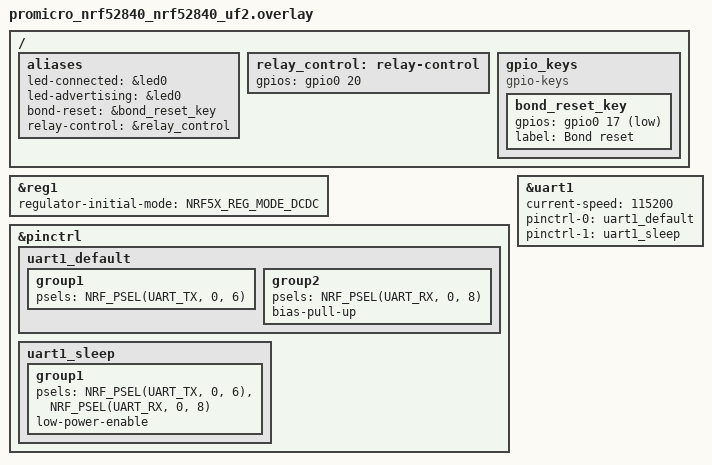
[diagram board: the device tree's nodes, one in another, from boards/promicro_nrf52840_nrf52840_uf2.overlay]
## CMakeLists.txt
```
cmake_minimum_required(VERSION 3.20.0)
find_package(Zephyr REQUIRED HINTS $ENV{ZEPHYR_BASE})

project(nrfProxy)

target_sources(app PRIVATE
	src/main.c
	src/proxy_core.c
	src/uart_bridge.c
	src/uart_rx_retry.c
	src/drop_stats.c
)
```

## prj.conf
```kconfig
# ---------------------------------------------------------------------------
# nrfProxy: forward incoming UART1 serial data to a phone over BLE (NUS)
# ---------------------------------------------------------------------------

# --- Bluetooth: BLE peripheral exposing the Nordic UART Service -------------
CONFIG_BT=y
CONFIG_BT_PERIPHERAL=y
CONFIG_BT_DEVICE_NAME="nrfProxy"
CONFIG_BT_MAX_CONN=1

# Per-device identity (see identity_init() in main.c): derive a stable
# random-static BT address and a unique "nrfProxy-XXXX" name suffix from the
# SoC's hardware ID, so multiple units are distinguishable over the air.
# HWINFO exposes that hardware ID; DEVICE_NAME_DYNAMIC lets bt_set_name() set
# the runtime name (MAX must fit "nrfProxy-XXXX").
CONFIG_HWINFO=y
CONFIG_BT_DEVICE_NAME_DYNAMIC=y
CONFIG_BT_DEVICE_NAME_MAX=20

# Nordic UART Service (NUS) — the GATT service the phone subscribes to
CONFIG_BT_NUS=y

# --- Pairing / bond-lock (see PAIRING_PLAN.md) -----------------------------
# Once a phone pairs, only that phone can reconnect: the bond is stored in
# flash, the filter accept list rejects everyone else at the link layer, and
# the link must reach security level 2 (encryption) before NUS data flows.
# A hardware button held during boot wipes the bond (back to pairing mode).
#
# Just Works pairing (no display/keypad -> unauthenticated but encrypted).
# CONFIG_BT_NUS_AUTHEN is deliberately NOT set: it demands MITM-authenticated
# pairing, which Just Works can never satisfy — encryption is enforced in the
# application layer instead (security_changed + a watchdog in main.c).
# MAX_PAIRED=1 makes the stack reject any second bond. These stay in prj.conf
# (not prod.conf): production needs the lock most of all.
CONFIG_BT_SMP=y
CONFIG_BT_BONDABLE=y
CONFIG_BT_MAX_PAIRED=1
CONFIG_BT_FILTER_ACCEPT_LIST=y

# Bond persistence: the settings subsystem stores the LTK/IRK in NVS in the DT
# storage_partition (all four boards define one — no overlay change needed).
# The bond survives power loss until the reset button wipes it.
CONFIG_BT_SETTINGS=y
CONFIG_SETTINGS=y
CONFIG_FLASH=y
CONFIG_FLASH_MAP=y
CONFIG_NVS=y

# Throughput: negotiate a larger ATT MTU and LL data length so we can push
# up to ~244 bytes per notification instead of the 20-byte default.
CONFIG_BT_L2CAP_TX_MTU=247
CONFIG_BT_BUF_ACL_TX_SIZE=251
CONFIG_BT_BUF_ACL_RX_SIZE=251
CONFIG_BT_CTLR_DATA_LENGTH_MAX=251

# --- Serial: async UART driver for the incoming data on UART1 --------------
CONFIG_SERIAL=y
CONFIG_UART_ASYNC_API=y
# uart1 is our async data port. The per-instance UART_1_ASYNC depends on
# !UART_1_INTERRUPT_DRIVEN, and UART_1_INTERRUPT_DRIVEN defaults y whenever
# anything enables CONFIG_UART_INTERRUPT_DRIVEN (e.g. the XIAO BLE's USB CDC
# console). Without this, uart_callback_set() returns -ENOSYS (-88) on those
# boards. Force it off so uart1 keeps the async API everywhere.
CONFIG_UART_1_INTERRUPT_DRIVEN=n
# Runtime baud change: the phone switches uart1's baud on the fly (different
# motor controllers talk at 1200..115200) via uart_configure() in uart_bridge.c.
# Without this, uart_configure()/uart_config_get() return -ENOSYS.
CONFIG_UART_USE_RUNTIME_CONFIGURE=y

# --- Misc ------------------------------------------------------------------
CONFIG_HEAP_MEM_POOL_SIZE=2048

# GPIO for the status LEDs
CONFIG_GPIO=y

# Logging on the default console (board-dependent: J-Link VCOM on the DK,
# USB CDC-ACM on the XIAO BLE)
CONFIG_LOG=y

# Board-specific debug/optimization settings live in the per-board fragments under
# boards/ that Zephyr auto-merges on top of this file — see README.md
# ("Per-board Kconfig fragments") for the full list.
```

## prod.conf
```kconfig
# No logging subsystem / output.
CONFIG_LOG=n

# Drop the USB CDC-ACM serial backend. On the XIAO this Kconfig (default y)
# pulls in the USB device stack and initialises CDC-ACM as the console at boot;
# turning it off removes USB bring-up entirely. The console then has no backend.
CONFIG_BOARD_SERIAL_BACKEND_CDC_ACM=n
CONFIG_CONSOLE=n
CONFIG_UART_CONSOLE=n
```

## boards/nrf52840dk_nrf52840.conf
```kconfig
# Board-specific Kconfig for the nRF52840 DK (bench/debug board).
# Auto-merged on top of prj.conf by Zephyr for `-b nrf52840dk/nrf52840`.
#
# Build at -Og and expose thread info so the SWD/J-Link debugger in VS Code
# can place breakpoints and enumerate threads. The XIAO (production) omits
# these for a smaller/faster -Os build.
CONFIG_DEBUG_OPTIMIZATIONS=y
CONFIG_DEBUG_THREAD_INFO=y
```

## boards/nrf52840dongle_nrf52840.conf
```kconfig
# Board-specific Kconfig for the Nordic nRF52840 Dongle (PCA10059).
# Auto-merged on top of prj.conf by Zephyr for `-b nrf52840dongle/nrf52840`.
#
# Debug/bench board: keep logging + the USB CDC-ACM console (the dongle has no
# debugger / VCOM). prj.conf already enables logging, so "debug output" works out
# of the box; these are the debug-build niceties on top.

# Debug aids (same as the DK's .conf): -Og and thread metadata for a debugger.
CONFIG_DEBUG_OPTIMIZATIONS=y
CONFIG_DEBUG_THREAD_INFO=y

# USB device controller buffer pool. The 1024-byte default is too small for the
# large control transfers a Windows host issues during enumeration, so EP0
# allocations fail ("udc: Failed to allocate net_buf 4095, ep 0x80") and log
# output over USB CDC-ACM is disrupted. Size the pool past the request.
# (Same issue as the XIAO / Pro Micro — Zephyr issue #85108.)
CONFIG_UDC_BUF_POOL_SIZE=8192

# Note: CONFIG_UART_1_INTERRUPT_DRIVEN=n lives in prj.conf (global) so uart1's
# async API isn't gated by the USB CDC-ACM console's CONFIG_UART_INTERRUPT_DRIVEN
# (the -ENOSYS trap documented in CLAUDE.md). It applies here too.
```

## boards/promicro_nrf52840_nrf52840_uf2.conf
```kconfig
# Board-specific Kconfig for the "Pro Micro nRF52840" / nice!nano clone.
# Auto-merged on top of prj.conf by Zephyr for `-b promicro_nrf52840/nrf52840[/uf2]`.
#
# Debug/bring-up build: keep the USB CDC-ACM console + logging (this board has no
# debug UART). For battery/production, layer prod.conf on top via EXTRA_CONF_FILE
# into a separate build dir, exactly like the XIAO (see prod.conf / CLAUDE.md).

# USB device controller buffer pool. The 1024-byte default is too small for the
# large control transfers a Windows host issues during enumeration, so EP0
# allocations fail ("udc: Failed to allocate net_buf 4095, ep 0x80") and log
# output over USB CDC-ACM is disrupted. Size the pool past the request.
# (Same issue as the XIAO — Zephyr issue #85108.)
CONFIG_UDC_BUF_POOL_SIZE=8192

# Note: CONFIG_UART_1_INTERRUPT_DRIVEN=n lives in prj.conf (global) so uart1's
# async API isn't gated by the USB CDC-ACM console's CONFIG_UART_INTERRUPT_DRIVEN
# (the -ENOSYS trap documented in CLAUDE.md). It applies here too.

# Low-frequency clock source: no override here on purpose. The promicro_nrf52840
# board target already defaults to the external 32.768 kHz crystal
# (CONFIG_CLOCK_CONTROL_NRF_K32SRC_XTAL), which this board populates — better
# accuracy / lower power than the internal RC. If you flash a crystal-less clone
# (many cheap Pro Micro / "SuperMini" boards omit the 32 kHz crystal), add
# CONFIG_CLOCK_CONTROL_NRF_K32SRC_RC=y + CONFIG_CLOCK_CONTROL_NRF_K32SRC_500PPM=y,
# or LFCLK never starts and the BLE controller blocks at bt_enable().
```

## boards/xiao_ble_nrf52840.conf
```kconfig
# Board-specific Kconfig for the Seeed XIAO BLE (production board).
# Auto-merged on top of prj.conf by Zephyr for `-b xiao_ble/nrf52840`.
#
# Production build: optimize for size, no debug build options. Logging still
# works (over USB CDC-ACM); this only drops the -Og/thread-info debug aids.
CONFIG_SIZE_OPTIMIZATIONS=y

# USB device controller buffer pool. The 1024-byte default is too small for the
# large control transfers a Windows host issues during enumeration, so EP0
# allocations fail ("udc: Failed to allocate net_buf 4095, ep 0x80") and log
# output over USB CDC-ACM is disrupted. Size the pool past the request.
# (Zephyr issue #85108.)
CONFIG_UDC_BUF_POOL_SIZE=8192
```

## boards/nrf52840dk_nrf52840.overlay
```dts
/*
 * nrfProxy — UART1 for incoming serial data on the nRF52840 DK.
 *
 * Wiring (share a common GND with your serial source!):
 *   Device TX  ->  P1.01  (DK RX)   serial device -> phone
 *   Device RX  <-  P1.02  (DK TX)   phone -> serial device
 *
 * P1.01 / P1.02 are free on the DK (no LED/button/QSPI/NFC conflict) and are
 * broken out on the GPIO headers. Change current-speed below to match your
 * source's baud rate (defaults to 115200).
 */

#include <zephyr/dt-bindings/pinctrl/nrf-pinctrl.h>
#include <zephyr/dt-bindings/gpio/gpio.h>

/ {
	/* Status-LED roles -> three of the DK's LEDs (LED2/LED3/LED4). */
	aliases {
		led-connected = &led1;
		led-advertising = &led2;
		led-error = &led3;

		/* Bond-reset: hold Button 1 (SW1, P0.11) through boot ~3 s to
		 * wipe the stored pairing. The board node already carries
		 * GPIO_PULL_UP | GPIO_ACTIVE_LOW. */
		bond-reset = &button0;

		/* Relay-control output the phone toggles over BLE (motor enable).
		 * P1.04 is free and broken out on the DK headers. Active-high by
		 * default (pin high = relay energised / motor enabled); change to
		 * GPIO_ACTIVE_LOW for an active-low relay module. */
		relay-control = &relay_control;
	};

	relay_control: relay-control {
		gpios = <&gpio1 4 GPIO_ACTIVE_HIGH>;
	};
};

&pinctrl {
	uart1_default: uart1_default {
		group1 {
			psels = <NRF_PSEL(UART_TX, 1, 2)>,
				<NRF_PSEL(UART_RX, 1, 1)>;
		};
	};

	uart1_sleep: uart1_sleep {
		group1 {
			psels = <NRF_PSEL(UART_TX, 1, 2)>,
				<NRF_PSEL(UART_RX, 1, 1)>;
			low-power-enable;
		};
	};
};

&uart1 {
	status = "okay";
	current-speed = <115200>;
	pinctrl-0 = <&uart1_default>;
	pinctrl-1 = <&uart1_sleep>;
	pinctrl-names = "default", "sleep";
};
```

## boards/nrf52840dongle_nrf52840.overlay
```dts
/*
 * nrfProxy — UART1 for incoming serial data on the Nordic nRF52840 Dongle
 * (PCA10059). This is a debug/bench board: console + logging come out the USB
 * CDC-ACM serial port (the dongle has no debugger / no VCOM).
 *
 * The dongle ships with the Nordic Open USB bootloader (no J-Link). Flash by
 * DFU, not `west flash`/J-Link — see "nRF52840 Dongle" in CLAUDE.md. The app
 * links at flash offset 0x1000 (right after the factory MBR).
 *
 * Wiring (share a common GND with your serial source!):
 *   Device TX  ->  P0.13  (dongle RX)   serial device -> phone
 *   Device RX  <-  P0.15  (dongle TX)   phone -> serial device
 *
 * P0.13 / P0.15 are free, broken-out castellated pads (uart0=P0.20/17/24/22,
 * i2c0=P0.26/27, spi1=P0.31/30/P1.13, LEDs/pwm0=P0.06/08/P1.09/P0.12 are taken).
 * Change current-speed to match your source's baud rate (defaults to 115200).
 *
 * DC/DC: the dongle's board dts already enables REG1 in DC/DC mode (it has the
 * inductor), so there's nothing to add here.
 */

#include <zephyr/dt-bindings/pinctrl/nrf-pinctrl.h>
#include <zephyr/dt-bindings/gpio/gpio.h>

/ {
	/*
	 * Status-LED roles -> the dongle's RGB LED (LD2), all active-low. Unlike the
	 * single-LED Pro Micro, the dongle has a full RGB LED, so the error role gets
	 * its own (red) colour here.
	 */
	aliases {
		led-connected = &led1_green;    /* P1.09 green */
		led-advertising = &led1_blue;   /* P0.12 blue  */
		led-error = &led1_red;          /* P0.08 red   */

		/* Bond-reset: hold SW1 (the top-face button, P1.06 — NOT the
		 * side RESET) through boot ~3 s to wipe the stored pairing. The
		 * board node already carries GPIO_PULL_UP | GPIO_ACTIVE_LOW. */
		bond-reset = &button0;

		/* Relay-control output the phone toggles over BLE (motor enable).
		 * P1.10 is a free broken-out castellated pad (uart1 P0.13/15,
		 * uart0 P0.20/17/24/22, i2c0 P0.26/27, spi1 P0.31/30/P1.13, LEDs
		 * P0.06/08/12 + P1.09, SW1 P1.06 are taken). Active-high; use
		 * GPIO_ACTIVE_LOW for an active-low relay module. */
		relay-control = &relay_control;
	};

	relay_control: relay-control {
		gpios = <&gpio1 10 GPIO_ACTIVE_HIGH>;
	};

	/*
	 * The board routes these RGB LED pins through pwm0 (pwmleds). We drive them
	 * as plain GPIOs, so disable the PWM peripheral and the pwm-leds node to avoid
	 * two drivers claiming the same pins.
	 */
	pwmleds {
		status = "disabled";
	};
};

&pwm0 {
	status = "disabled";
};

&pinctrl {
	uart1_default: uart1_default {
		group1 {
			psels = <NRF_PSEL(UART_TX, 0, 15)>;
		};
		group2 {
			psels = <NRF_PSEL(UART_RX, 0, 13)>;
			bias-pull-up;
		};
	};

	uart1_sleep: uart1_sleep {
		group1 {
			psels = <NRF_PSEL(UART_TX, 0, 15)>,
				<NRF_PSEL(UART_RX, 0, 13)>;
			low-power-enable;
		};
	};
};

&uart1 {
	status = "okay";
	current-speed = <115200>;
	pinctrl-0 = <&uart1_default>;
	pinctrl-1 = <&uart1_sleep>;
	pinctrl-names = "default", "sleep";
};
```

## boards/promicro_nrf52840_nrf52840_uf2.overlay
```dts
/*
 * nrfProxy — UART1 for incoming serial data on the "Pro Micro nRF52840" / nice!nano
 * clone (nRF52840 in Pro Micro form factor, Adafruit UF2 bootloader).
 *
 * This board has NO debugger — flash by double-tapping RESET to mount the
 * bootloader's USB mass-storage drive and copying build_promicro/zephyr/zephyr.uf2
 * onto it. Build the UF2 variant: -b promicro_nrf52840/nrf52840/uf2 (the app must
 * land at flash offset 0x26000, which that variant arranges).
 *
 * Wiring (share a common GND with your serial source!):
 *   Device TX  ->  P0.08  (board RX)   serial device -> phone
 *   Device RX  <-  P0.06  (board TX)   phone -> serial device
 *
 * P0.06 / P0.08 are the silkscreen TX/RX pads on the nice!nano edge and are free
 * on this board (uart0=P0.09/10, i2c0=P1.00/P0.11, i2c1=P1.04/P1.06,
 * spi2=P1.01/P1.02/P1.07, led/pwm0=P0.15 are all taken). Console/logs are over
 * USB CDC-ACM (no debug UART). Change current-speed to match your source's baud
 * rate (defaults to 115200).
 *
 * DC/DC regulator (&reg1) is ENABLED below for lower active/radio current. The
 * genuine nice!nano has the required DCC/DEC4 inductor populated (Board-ID
 * nRF52840-nicenano). A board that lacks that inductor would brown out — disable
 * this block if you flash a stripped clone.
 */

#include <zephyr/dt-bindings/pinctrl/nrf-pinctrl.h>
#include <zephyr/dt-bindings/regulator/nrf5x.h>
#include <zephyr/dt-bindings/gpio/gpio.h>

/*
 * Enable the nRF52840's main DC/DC regulator (REG1) for lower active/radio
 * current than the default LDO. Requires the external inductor between DCC and
 * DEC4, which the nice!nano has populated. VDDH is tied to VDD (normal-voltage
 * mode), so REG0 is unused and left alone. Disable this block if you flash a
 * stripped clone that lacks the inductor — it would brown out otherwise.
 */
&reg1 {
	regulator-initial-mode = <NRF5X_REG_MODE_DCDC>;
};

/ {
	/*
	 * Status-LED roles. This board has a single LED (led0 = P0.15, active-high).
	 * Connected (solid) and advertising (blink) share it — the states are mutually
	 * exclusive, so it's unambiguous. led-error is intentionally left UNMAPPED:
	 * main.c's GPIO_DT_SPEC_GET_OR falls back to a null spec and skips it, so the
	 * error state lights no LED (by request).
	 */
	aliases {
		led-connected = &led0;
		led-advertising = &led0;
		/* led-error deliberately omitted -> no LED on error. */

		/* Bond-reset button on the P0.17 pad (see the gpio-keys node
		 * below). Hold to GND through boot ~3 s to wipe the pairing. */
		bond-reset = &bond_reset_key;

		/* Relay-control output the phone toggles over BLE (motor enable).
		 * P0.20 is a free broken-out pad (uart1 P0.06/08, LED P0.15,
		 * bond-reset P0.17 are taken); alternates P0.22/24/29/31,
		 * P1.11/13/15. Active-high; use GPIO_ACTIVE_LOW for an active-low
		 * relay module. */
		relay-control = &relay_control;
	};

	relay_control: relay-control {
		gpios = <&gpio0 20 GPIO_ACTIVE_HIGH>;
	};

	/*
	 * No on-board user button. Wire a momentary switch from the P0.17 pad to
	 * GND — it sits directly below the two GND pads on the left edge, so a
	 * two-pin button bridges it naturally. Internal pull-up + active-low, so
	 * "pressed" = shorted to GND. P0.17 is free (uart0 P0.09/10, i2c0
	 * P1.00/P0.11, i2c1 P1.04/P1.06, spi2 P1.01/02/07, LED P0.15, uart1
	 * P0.06/08 are taken); alternates: P0.20/22/24/29/31, P1.11/13/15.
	 */
	gpio_keys {
		compatible = "gpio-keys";
		bond_reset_key: bond_reset_key {
			gpios = <&gpio0 17 (GPIO_PULL_UP | GPIO_ACTIVE_LOW)>;
			label = "Bond reset";
		};
	};
};

&pinctrl {
	uart1_default: uart1_default {
		group1 {
			psels = <NRF_PSEL(UART_TX, 0, 6)>;
		};
		group2 {
			psels = <NRF_PSEL(UART_RX, 0, 8)>;
			bias-pull-up;
		};
	};

	uart1_sleep: uart1_sleep {
		group1 {
			psels = <NRF_PSEL(UART_TX, 0, 6)>,
				<NRF_PSEL(UART_RX, 0, 8)>;
			low-power-enable;
		};
	};
};

&uart1 {
	status = "okay";
	current-speed = <115200>;
	pinctrl-0 = <&uart1_default>;
	pinctrl-1 = <&uart1_sleep>;
	pinctrl-names = "default", "sleep";
};
```

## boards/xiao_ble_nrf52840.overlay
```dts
/*
 * nrfProxy — UART1 for incoming serial data on the Seeed XIAO BLE (nRF52840).
 *
 * Uses UARTE1 (independent of the board's uart0/i2c1/spi2), routed to two of
 * the free castellated pads. Wiring (share a common GND with your source!):
 *   Device TX  ->  D1 / P0.03  (XIAO RX)   serial device -> phone
 *   Device RX  <-  D0 / P0.02  (XIAO TX)   phone -> serial device
 *
 * D0/D1 are otherwise unused (D4/D5=I2C, D6/D7=uart0, D8-D10=SPI are taken).
 * The console/log output is over USB CDC-ACM on this board (no debug UART),
 * so view logs on the USB serial port, not a pad. Change current-speed to
 * match your source's baud rate (defaults to 115200).
 */

#include <zephyr/dt-bindings/pinctrl/nrf-pinctrl.h>
#include <zephyr/dt-bindings/regulator/nrf5x.h>
#include <zephyr/dt-bindings/gpio/gpio.h>

/*
 * Enable the nRF52840's main DC/DC regulator (REG1) for lower active/radio
 * current than the default LDO. Requires the external inductor between DCC and
 * DEC4, which the XIAO BLE has populated. VDDH is tied to VDD (normal-voltage
 * mode), so REG0 is unused and left alone.
 */
&reg1 {
	regulator-initial-mode = <NRF5X_REG_MODE_DCDC>;
};

/ {
	/* Status-LED roles -> the XIAO's on-board RGB LED (all active-low). */
	aliases {
		led-connected = &led1;    /* green */
		led-advertising = &led2;  /* blue  */
		led-error = &led0;        /* red   */

		/* Bond-reset button on the D2 pad (see the gpio-keys node
		 * below). Hold to GND through boot ~3 s to wipe the pairing. */
		bond-reset = &bond_reset_key;

		/* Relay-control output the phone toggles over BLE (motor enable).
		 * D3 / P0.29 is the only remaining free pad (D0/D1 = uart1,
		 * D2 = bond-reset, D4/D5 = i2c1, D6/D7 = uart0, D8-D10 = spi2).
		 * Active-high; use GPIO_ACTIVE_LOW for an active-low relay. */
		relay-control = &relay_control;
	};

	relay_control: relay-control {
		gpios = <&gpio0 29 GPIO_ACTIVE_HIGH>;
	};

	/*
	 * The XIAO has no on-board user button. Wire a momentary switch (or a
	 * tweezer short) from the D2 pad (P0.28) to GND; the internal pull-up +
	 * active-low means "pressed" = shorted to GND. D2/D3 are the only free
	 * pads (D0/D1 = uart1, D4/D5 = i2c1, D6/D7 = uart0, D8-D10 = spi2). Use
	 * D3 = P0.29 instead by changing the pin below.
	 */
	gpio_keys {
		compatible = "gpio-keys";
		bond_reset_key: bond_reset_key {
			gpios = <&gpio0 28 (GPIO_PULL_UP | GPIO_ACTIVE_LOW)>;
			label = "Bond reset";
		};
	};
};

&pinctrl {
	uart1_default: uart1_default {
		group1 {
			psels = <NRF_PSEL(UART_TX, 0, 2)>;
		};
		group2 {
			psels = <NRF_PSEL(UART_RX, 0, 3)>;
			bias-pull-up;
		};
	};

	uart1_sleep: uart1_sleep {
		group1 {
			psels = <NRF_PSEL(UART_TX, 0, 2)>,
				<NRF_PSEL(UART_RX, 0, 3)>;
			low-power-enable;
		};
	};
};

&uart1 {
	status = "okay";
	current-speed = <115200>;
	pinctrl-0 = <&uart1_default>;
	pinctrl-1 = <&uart1_sleep>;
	pinctrl-names = "default", "sleep";
};
```

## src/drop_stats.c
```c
#include "drop_stats.h"

uint32_t drop_stats_rx_overflow(uint32_t attempted, uint32_t queued)
{
	return (queued < attempted) ? (attempted - queued) : 0;
}

bool drop_stats_should_report(uint32_t now_ms, uint32_t last_report_ms,
			      uint32_t interval_ms, bool counters_changed)
{
	if (!counters_changed) {
		return false;
	}
	return (now_ms - last_report_ms) >= interval_ms;
}
```

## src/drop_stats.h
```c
/*
 * Silent-drop accounting (ISR-safe counters + thread-context report policy).
 */
#ifndef DROP_STATS_H_
#define DROP_STATS_H_

#include <stdbool.h>
#include <stdint.h>

#ifdef __cplusplus
extern "C" {
#endif

/* Bytes not written by ring_buf_put (attempted - queued). */
uint32_t drop_stats_rx_overflow(uint32_t attempted, uint32_t queued);

/* True when a periodic report should fire (changed since last AND interval elapsed). */
bool drop_stats_should_report(uint32_t now_ms, uint32_t last_report_ms,
			      uint32_t interval_ms, bool counters_changed);

#ifdef __cplusplus
}
#endif

#endif /* DROP_STATS_H_ */
```

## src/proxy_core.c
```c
/*
 * proxy_core — pure logic, no Zephyr. See proxy_core.h for the rule and why.
 */

#include <errno.h>
#include <stdio.h>
#include <string.h>

#include "proxy_core.h"

/* --- Interception hooks --------------------------------------------------- */

size_t on_uart_rx(const uint8_t *in, size_t in_len, uint8_t *out, size_t out_size)
{
	size_t n = (in_len < out_size) ? in_len : out_size;

	memcpy(out, in, n);
	return n;
}

size_t on_ble_rx(const uint8_t *in, size_t in_len, uint8_t *out, size_t out_size)
{
	size_t n = (in_len < out_size) ? in_len : out_size;

	memcpy(out, in, n);
	return n;
}

/* --- Device-control command ----------------------------------------------- */

/* 8-bit additive checksum over the packet's bytes preceding the checksum byte.
 * Trivial on purpose: the encrypted link, not this byte, is the security
 * boundary — it only catches a corrupted or mis-framed write. */
static uint8_t cmd_checksum(const uint8_t *in)
{
	uint8_t sum = 0;

	for (size_t i = 0; i < PROXY_CMD_PACKET_LEN - 1; i++) {
		sum = (uint8_t)(sum + in[i]);
	}
	return sum;
}

bool proxy_baud_supported(uint32_t baud)
{
	static const uint32_t supported[] = {
		1200, 9600, 19200, 38400, 57600, 115200,
	};

	for (size_t i = 0; i < sizeof(supported) / sizeof(supported[0]); i++) {
		if (baud == supported[i]) {
			return true;
		}
	}
	return false;
}

static uint32_t le32(const uint8_t *p)
{
	return (uint32_t)p[0] | ((uint32_t)p[1] << 8) |
	       ((uint32_t)p[2] << 16) | ((uint32_t)p[3] << 24);
}

enum proxy_cmd_kind proxy_cmd_parse(const uint8_t *in, size_t in_len,
				    struct proxy_cmd *out)
{
	const uint8_t *payload = &in[PROXY_CMD_PAYLOAD_OFF];

	out->kind = PROXY_CMD_NONE;
	out->baud = 0;
	out->ack_len = 0;

	/* Framing gate: anything that isn't exactly our 16-byte packet, with a
	 * self-consistent length and a good checksum, is treated as ordinary data
	 * and forwarded down the UART. */
	if (in_len != PROXY_CMD_PACKET_LEN ||
	    in[0] != PROXY_CMD_START ||
	    in[1] != PROXY_CMD_PACKET_LEN ||
	    in[PROXY_CMD_PACKET_LEN - 1] != cmd_checksum(in)) {
		return PROXY_CMD_NONE;
	}

	/* Framed for us: from here on it is never forwarded as data, even when
	 * the opcode or payload is bad (that becomes PROXY_CMD_INVALID). */
	switch (in[2]) {
	case PROXY_OP_RELAY:
		if (payload[0] == 0) {
			out->kind = PROXY_CMD_RELAY_DISABLE;
		} else if (payload[0] == 1) {
			out->kind = PROXY_CMD_RELAY_ENABLE;
		} else {
			out->kind = PROXY_CMD_INVALID;
		}
		break;
	case PROXY_OP_BAUD: {
		uint32_t baud = le32(payload);

		if (proxy_baud_supported(baud)) {
			out->kind = PROXY_CMD_SET_BAUD;
			out->baud = baud;
		} else {
			out->kind = PROXY_CMD_INVALID;
		}
		break;
	}
	default:
		out->kind = PROXY_CMD_INVALID;
		break;
	}

	/* Echo the exact packet back for an actionable command; an INVALID one is
	 * silently dropped (no ack), so the phone can distinguish "took effect"
	 * from "refused" by whether the echo arrives. */
	if (out->kind != PROXY_CMD_INVALID) {
		memcpy(out->ack, in, PROXY_CMD_PACKET_LEN);
		out->ack_len = PROXY_CMD_PACKET_LEN;
	}

	return out->kind;
}

/* --- Per-device identity -------------------------------------------------- */

/* The two MSBs of the top address byte mark an address static-random. Mirrors
 * Zephyr's BT_ADDR_SET_STATIC, spelled out here to keep the BT headers out. */
#define ADDR_STATIC_MSBS 0xc0

void proxy_identity_derive(const char *base_name, const uint8_t *hwid,
			   int hwid_len, struct proxy_identity *out)
{
	size_t base_len = strlen(base_name);

	/* Truncate rather than overflow. main.c BUILD_ASSERTs that the real
	 * name plus its suffix fits, so this only bites a caller passing an
	 * over-long base name — a unit test, or a future rename. */
	if (base_len > sizeof(out->name) - 1) {
		base_len = sizeof(out->name) - 1;
	}

	/* Zero the whole buffer, not just the terminator: it makes the
	 * derivation byte-deterministic rather than only string-deterministic,
	 * so the tail can't carry whatever the caller's memory happened to hold
	 * into advertising data. */
	memset(out->name, 0, sizeof(out->name));
	memcpy(out->name, base_name, base_len);
	out->addr_valid = false;

	if (hwid == NULL || hwid_len < PROXY_HWID_MIN_LEN) {
		return;
	}

	/* Fixed static-random address from the low 6 bytes of the chip id. */
	memcpy(out->addr, hwid, PROXY_ADDR_LEN);
	out->addr[PROXY_ADDR_LEN - 1] |= ADDR_STATIC_MSBS;

	/* Per-device id for the manufacturer advertising data. */
	memcpy(out->mfg_id, hwid, PROXY_MFG_ID_LEN);

	out->addr_valid = true;

	/* Unique name suffix from the top id bytes (e.g. "nrfProxy-3F7A"). */
	if (base_len + sizeof("-XXXX") <= sizeof(out->name)) {
		snprintf(out->name + base_len, sizeof("-XXXX"), "-%02X%02X",
			 hwid[5], hwid[4]);
	}
}

/* --- Link / advertising policy -------------------------------------------- */

bool proxy_should_start_adv(const struct proxy_link_state *state)
{
	return !state->connected && !state->adv_active;
}

bool proxy_may_forward(const struct proxy_link_state *state)
{
	return state->connected && state->link_secure;
}

uint32_t proxy_security_window_ms(bool locked_mode)
{
	/* One window for both modes now — see PROXY_SECURITY_WINDOW_MS for why
	 * locked mode can no longer use the short one. The parameter stays so the
	 * call site keeps reading naturally and the tests can pin that the two
	 * modes agree. */
	(void)locked_mode;
	return PROXY_SECURITY_WINDOW_MS;
}

/* --- NUS send policy ------------------------------------------------------ */

uint16_t proxy_nus_chunk_limit(uint16_t att_mtu)
{
	if (att_mtu > PROXY_ATT_HEADER_LEN) {
		return (uint16_t)(att_mtu - PROXY_ATT_HEADER_LEN);
	}
	return PROXY_NUS_CHUNK_FALLBACK;
}

size_t proxy_next_slice(size_t out_len, size_t sent, uint16_t max_send)
{
	size_t remaining;

	if (sent >= out_len) {
		return 0;
	}

	remaining = out_len - sent;
	return (remaining < max_send) ? remaining : max_send;
}

enum proxy_send_verdict proxy_send_result(int bt_nus_send_err)
{
	switch (bt_nus_send_err) {
	case 0:
		return PROXY_SEND_CONSUMED;
	case -ENOMEM:
	case -EAGAIN:
		return PROXY_SEND_RETRY;
	default:
		return PROXY_SEND_DROP;
	}
}
```

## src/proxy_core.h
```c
/*
 * proxy_core — the parts of nrfProxy that are decisions rather than plumbing.
 *
 * main.c owns every Zephyr and Bluetooth API call, all the locking, and all the
 * callbacks; this file owns the logic they decide with. The split exists so the
 * logic can be unit-tested (tests/unit/) without a BLE stack, a UART, or a
 * board.
 *
 * The binding rule, and the reason the types below look the way they do:
 * **nothing here may depend on Zephyr.** No kernel objects, no BT host calls, no
 * logging, no Kconfig symbols, no statics. So an address crosses the boundary as
 * six plain bytes rather than a bt_addr_le_t, and a timeout as milliseconds
 * rather than a k_timeout_t; main.c converts at the call site and BUILD_ASSERTs
 * the couplings. That keeps the suites buildable on native_sim with no BT
 * config, and compilable straight on a host with plain gcc.
 */
#ifndef PROXY_CORE_H_
#define PROXY_CORE_H_

#include <stdbool.h>
#include <stddef.h>
#include <stdint.h>

#ifdef __cplusplus
extern "C" {
#endif

/* --- Interception hooks --------------------------------------------------- */
/*
 * Called for each chunk of data as it is received, before it is forwarded on.
 * Right now they copy the input straight through, unmodified. To inspect,
 * modify, filter, or append to the data, edit the bodies: write whatever you
 * want forwarded into `out` (up to `out_size` bytes) and return how many bytes
 * you wrote. Return 0 to drop the data entirely.
 *
 * `out` is a separate scratch buffer (not the receive buffer), so you can grow
 * the data up to PROC_BUF_SIZE. Bump PROC_BUF_SIZE if you need more headroom.
 *
 * Both run in thread context — on_uart_rx in ble_write_thread, on_ble_rx in the
 * Bluetooth RX thread — so real filter/framing logic is fine here. (on_uart_rx
 * used to run in the UART ISR; that was moved deliberately, because an ISR is
 * the wrong place for the work these hooks exist for.)
 *
 * Both see transport **chunks**, not framed application messages: on_ble_rx gets
 * one GATT write; on_uart_rx gets whatever the RX ring held contiguously, capped
 * at one notification's worth — which is *not* the UART's chunking. Nothing
 * preserves message boundaries; add reassembly if the data is message-oriented.
 */
#define PROC_BUF_SIZE 512

/* Serial -> phone: bytes received on UART1, before they go out over BLE. */
size_t on_uart_rx(const uint8_t *in, size_t in_len, uint8_t *out, size_t out_size);

/* Phone -> serial: bytes received over BLE, before they go out UART1. */
size_t on_ble_rx(const uint8_t *in, size_t in_len, uint8_t *out, size_t out_size);

/* --- Device-control command (phone -> device) ----------------------------- */
/*
 * A fixed-width 16-byte framed command the phone sends over NUS to control
 * *this* device (drive the relay GPIO, change the UART baud, …), rather than to
 * be forwarded down the UART. The width is fixed so the format never has to grow
 * again: a new control takes a new opcode and reuses the spare payload bytes.
 *
 *   [0]     start    = PROXY_CMD_START (0x22)
 *   [1]     length   = PROXY_CMD_PACKET_LEN (16) — declared length, must match
 *   [2]     opcode   = PROXY_OP_* (which control)
 *   [3..14] payload  = opcode-specific (unused bytes zero)
 *   [15]    checksum = sum(in[0..14]) & 0xFF   (8-bit additive sum)
 *
 * The BLE link is already encrypted (pairing lock), so the checksum only guards
 * against corruption / accidental framing, not tampering.
 *
 * Opcodes and their payloads:
 *   PROXY_OP_RELAY (0x01): payload[0] = 0 disable / 1 enable the relay pin.
 *   PROXY_OP_BAUD  (0x02): payload[0..3] = new UART baud, uint32 little-endian.
 *                          Only an allow-listed rate is accepted (see
 *                          proxy_baud_supported).
 *
 * On an actionable command main.c performs the action and echoes the *exact*
 * 16 bytes back to the phone as an acknowledgement, so the phone can confirm it
 * took effect.
 *
 * Classification (proxy_cmd_parse → struct proxy_cmd::kind):
 *   PROXY_CMD_NONE     framing did not validate (wrong start/length/checksum) —
 *                      not ours; forward down the UART as ordinary data.
 *   PROXY_CMD_INVALID  framed for us but the opcode is unknown or the payload is
 *                      out of range — consume it (a framed control packet is
 *                      never forwarded to the motor) but take no action and send
 *                      no ack.
 *   PROXY_CMD_RELAY_*  drive the relay pin (disable/enable).
 *   PROXY_CMD_SET_BAUD reconfigure the UART to `baud`.
 */
#define PROXY_CMD_START        0x22
#define PROXY_CMD_PACKET_LEN   16
#define PROXY_CMD_PAYLOAD_OFF  3    /* index of the first payload byte */

enum proxy_cmd_op {
	PROXY_OP_RELAY = 0x01,
	PROXY_OP_BAUD  = 0x02,
};

enum proxy_cmd_kind {
	PROXY_CMD_NONE = 0,     /* not a valid command — forward as UART data */
	PROXY_CMD_INVALID,      /* framed for us but bad opcode/payload — drop */
	PROXY_CMD_RELAY_DISABLE,
	PROXY_CMD_RELAY_ENABLE,
	PROXY_CMD_SET_BAUD,
};

struct proxy_cmd {
	enum proxy_cmd_kind kind;
	uint32_t baud;                      /* set for PROXY_CMD_SET_BAUD only */
	uint8_t ack[PROXY_CMD_PACKET_LEN];  /* echo bytes, actionable cmds only */
	size_t ack_len;                     /* 0 unless there is an ack to send */
};

/*
 * Whether `baud` is a UART rate this firmware will switch to. The nRF UARTE only
 * realises a fixed set of rates; this is the intersection with the ones the
 * e-bike controllers use (1200 for Bafang at the slow end, up to 115200).
 */
bool proxy_baud_supported(uint32_t baud);

/*
 * Classify a phone->device chunk and, for an actionable command, fill `out`
 * (which must be non-NULL) with the action, any parameters, and the ack bytes to
 * echo back. Returns out->kind. See the table above for what each kind means.
 */
enum proxy_cmd_kind proxy_cmd_parse(const uint8_t *in, size_t in_len,
				    struct proxy_cmd *out);

/* --- Per-device identity -------------------------------------------------- */

#define PROXY_ADDR_LEN         6   /* == BT_ADDR_SIZE */
#define PROXY_MFG_ID_LEN       4   /* per-device id in the manufacturer AD */
#define PROXY_DEVICE_NAME_MAX 20   /* <= CONFIG_BT_DEVICE_NAME_MAX + 1 */
#define PROXY_HWID_MIN_LEN     6   /* an address needs six bytes */

struct proxy_identity {
	/* Static-random address bytes, LSB first: main.c copies them into
	 * bt_addr_le_t.a.val and pairs them with BT_ADDR_LE_RANDOM. Only
	 * meaningful when addr_valid. */
	uint8_t addr[PROXY_ADDR_LEN];
	/* Advertised name ("nrfProxy-3F7A", or the base name alone when there is
	 * no hardware ID). Always NUL-terminated, and zero-padded to the full
	 * buffer so the derivation is byte-deterministic. */
	char name[PROXY_DEVICE_NAME_MAX];
	/* Per-device id for the manufacturer AD field. Left untouched when
	 * there is no hardware ID to derive it from. */
	uint8_t mfg_id[PROXY_MFG_ID_LEN];
	bool addr_valid;
};

/*
 * Derive a unit's identity from the SoC's unique hardware ID.
 *
 * Deterministic by design: the address is recomputed identically on every boot
 * rather than stored, which is what makes it stable without flash — and what
 * makes reboot-stability a property a unit test can check. Without it Zephyr
 * would generate a fresh random-static address from the RNG each boot and every
 * unit would advertise the same name.
 *
 * `hwid_len` is what hwinfo_get_device_id() returned, so it may be negative;
 * anything shorter than PROXY_HWID_MIN_LEN yields the fallback: `base_name`
 * alone, addr_valid = false, and mfg_id untouched.
 */
void proxy_identity_derive(const char *base_name, const uint8_t *hwid,
			   int hwid_len, struct proxy_identity *out);

/* --- Link / advertising policy -------------------------------------------- */

/* A snapshot of the state main.c guards with conn_mutex. Callers fill this in
 * under the lock and then decide outside it. */
struct proxy_link_state {
	bool connected;
	bool adv_active;
	bool link_secure;
	bool locked_mode;
};

/*
 * Whether advertising may be (re)started. Both halves of this guard were field
 * bugs, so treat it as load-bearing:
 *  - `connected`: with CONFIG_BT_MAX_CONN=1 a connectable start while a
 *    connection object is alive fails -ENOMEM and leaves the device unreachable
 *    until reboot.
 *  - `adv_active`: legacy connectable advertising pre-allocates a connection
 *    object, so bt_le_adv_stop() during the fast->slow switch fires the
 *    recycled callback too; without this flag that would start a second,
 *    competing advertiser (-EALREADY).
 */
bool proxy_should_start_adv(const struct proxy_link_state *state);

/* Whether NUS data may flow. Just Works pairing cannot satisfy BT_NUS_AUTHEN's
 * GATT permissions, so this app-level gate is the actual enforcement of the
 * pairing lock — not defence in depth over an already-closed door. */
bool proxy_may_forward(const struct proxy_link_state *state);

/*
 * How long a fresh link may stay unencrypted before the watchdog drops it.
 *
 * Flat 60 s for both pairing and locked mode (TODO_ARCHITECTURE Task 2):
 * disconnecting mid-SMP aborts pairing and Android reports "incorrect PIN";
 * locked mode needs the same window when the owner phone forgets the bond and
 * must re-pair (still passes the accept list). Long is safe — the filter
 * accept list is the real gate against strangers.
 */
#define PROXY_SECURITY_WINDOW_MS 60000U

uint32_t proxy_security_window_ms(bool locked_mode);

/* --- NUS send policy ------------------------------------------------------ */

#define PROXY_ATT_HEADER_LEN      3   /* notification opcode + handle */
#define PROXY_NUS_CHUNK_FALLBACK 20   /* minimum ATT MTU (23) - the header */

/* Largest notification payload for the negotiated ATT MTU. The MTU is re-read
 * per chunk because the peer can negotiate it up mid-connection; the fallback
 * covers a stack reporting a nonsense MTU. */
uint16_t proxy_nus_chunk_limit(uint16_t att_mtu);

/*
 * Size of the next notification to send from a hook's output buffer, given how
 * much has gone already. Returns 0 when there is nothing left.
 *
 * This exists because the hook may *grow* its input (up to PROC_BUF_SIZE = 512)
 * while a notification is capped at the ATT MTU (<= 244), so one claimed chunk
 * can need several sends. The ring bytes are already consumed by then -- the
 * data lives in the scratch buffer -- so a retry must resend from that buffer
 * and must never re-claim.
 */
size_t proxy_next_slice(size_t out_len, size_t sent, uint16_t max_send);

enum proxy_send_verdict {
	PROXY_SEND_CONSUMED,  /* copied into the GATT buffer — drop our copy */
	PROXY_SEND_RETRY,     /* no TX buffers right now — keep the data */
	PROXY_SEND_DROP,      /* disconnected / not subscribed — discard */
};

/* Classify a bt_nus_send() return. The stream is repetitive and loss-tolerant
 * by design, so everything that is not a transient buffer shortage drops rather
 * than back-pressures. */
enum proxy_send_verdict proxy_send_result(int bt_nus_send_err);

#ifdef __cplusplus
}
#endif

#endif /* PROXY_CORE_H_ */
```

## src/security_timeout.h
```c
/*
 * Single source of truth for the post-connect encryption watchdog window.
 *
 * One 60 s window for both pairing and locked mode — see the comment above
 * SECURITY_TIMEOUT in main.c (dialog-abort risk, bond-loss recovery, accept
 * list as the real gate).
 */
#ifndef SECURITY_TIMEOUT_H_
#define SECURITY_TIMEOUT_H_

#define SECURITY_TIMEOUT_MS 60000

#endif /* SECURITY_TIMEOUT_H_ */
```

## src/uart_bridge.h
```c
/*
 * uart_bridge — the UART side of the proxy: the async driver glue and the two
 * ring buffers that decouple the serial byte rate from BLE throughput.
 *
 * Deliberately free of any Bluetooth dependency, so it can be driven on
 * native_sim against an emulated UART (tests/integration/uart_bridge) with no
 * BLE stack. main.c owns everything BLE and calls in from both directions.
 *
 * Concurrency contract — this is the load-bearing part, and every rule here
 * exists because breaking it was a real bug:
 *
 *  - The RX ring is strictly single-producer (UART ISR) / single-consumer
 *    (whichever ONE thread calls the rx_* functions; in the app, ble_write_thread).
 *    Nothing else may touch it.
 *  - Consequently uart_bridge_rx_drain() flushes from the *consumer* side using
 *    claim/finish. ring_buf_reset() is forbidden: it rewrites both indices and
 *    corrupts the buffer against a concurrent ISR put.
 *  - uart_bridge_send() is the TX ring's only producer. The consumer is
 *    uart_tx_kick(), which runs from both thread and ISR context, so the
 *    in-progress flag is guarded with irq_lock().
 */
#ifndef UART_BRIDGE_H_
#define UART_BRIDGE_H_

#include <stdbool.h>
#include <stddef.h>
#include <stdint.h>

#include <zephyr/device.h>
#include <zephyr/kernel.h>

/*
 * Start receiving on `uart_dev`. `rx_data_ready` is given whenever RX bytes land
 * (binary semaphore: it means "there may be data", and the consumer is expected
 * to drain completely per wakeup).
 *
 * Returns 0, or a negative errno if the device is not ready or the async API is
 * unavailable (-ENOSYS means UART_<n>_INTERRUPT_DRIVEN got turned back on for
 * this instance -- see CLAUDE.md).
 */
int uart_bridge_init(const struct device *uart_dev, struct k_sem *rx_data_ready);

/* Phone -> serial: queue `len` bytes for transmission and start the pipeline.
 * Whatever does not fit is dropped (the stream is loss-tolerant by design) and
 * logged. Safe from thread context. */
void uart_bridge_send(const uint8_t *data, size_t len);

/*
 * Change the UART baud rate at runtime — for switching between motor controllers
 * that talk at different rates (1200..115200). Quiesces RX and TX, reconfigures,
 * and restarts reception; any in-flight or buffered bytes are dropped, which is
 * fine because a baud change means the peer on the other end just changed too.
 *
 * Returns 0 on success (the new rate is live), or a negative errno on failure,
 * in which case the previous rate stays in effect and reception is restarted.
 * **Thread context only** — it blocks briefly waiting for RX to stop; never call
 * it from an ISR. Serialise calls (the app only calls it from the BT RX thread).
 */
int uart_bridge_set_baud(uint32_t baud);

/* --- RX consumption. Consumer thread only (see the contract above). -------- */

bool uart_bridge_rx_is_empty(void);

/* Claim up to `max` contiguous bytes without consuming them; returns the count
 * and points `buf` at them. Follow with uart_bridge_rx_finish(). */
uint32_t uart_bridge_rx_claim(uint8_t **buf, uint32_t max);

/* Consume `consumed` of the claimed bytes (0 keeps them all for a later claim). */
void uart_bridge_rx_finish(uint32_t consumed);

/* Discard everything buffered, from the consumer side. */
void uart_bridge_rx_drain(void);

/* Periodic drop report for the consumer thread (ISR-safe counters, thread log). */
void uart_bridge_log_drops_if_due(void);

#endif /* UART_BRIDGE_H_ */
```

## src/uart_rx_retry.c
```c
#include <errno.h>

#include "uart_rx_retry.h"

bool uart_rx_enable_succeeded(int enable_err)
{
	return enable_err == 0 || enable_err == -EBUSY;
}

bool uart_rx_should_schedule_retry(bool alloc_ok, int enable_err)
{
	if (!alloc_ok) {
		return true;
	}
	return !uart_rx_enable_succeeded(enable_err);
}

bool uart_rx_retry_warn_once(bool *latched)
{
	if (*latched) {
		return false;
	}
	*latched = true;
	return true;
}

void uart_rx_retry_clear_latch(bool *latched)
{
	*latched = false;
}
```

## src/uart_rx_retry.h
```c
/*
 * UART async RX recovery policy (pure logic — host-testable without Zephyr).
 *
 * When UART_RX_DISABLED fails to re-enable, a delayed work item retries until
 * success. -EBUSY means another path already re-enabled — treat as success.
 */
#ifndef UART_RX_RETRY_H_
#define UART_RX_RETRY_H_

#include <stdbool.h>

#ifdef __cplusplus
extern "C" {
#endif

/* enable_err from uart_rx_enable(); 0 and -EBUSY both mean RX is live. */
bool uart_rx_enable_succeeded(int enable_err);

/* True when the ISR/work path should schedule (or re-schedule) the retry work. */
bool uart_rx_should_schedule_retry(bool alloc_ok, int enable_err);

/*
 * Once-per-outage warn latch: returns true the first time an outage is
 * observed; subsequent failures return false until cleared on success.
 */
bool uart_rx_retry_warn_once(bool *latched);

void uart_rx_retry_clear_latch(bool *latched);

#ifdef __cplusplus
}
#endif

#endif /* UART_RX_RETRY_H_ */
```
